# STM32F205RBT6 register map
File version: 1.0
Registers are 32-bit, access not given, reset 0x0 unless marked. A register's access mark holds for its fields unless they carry their own. Offsets are from the block's base; [hi:lo] are bit positions; {n}, {i} and the like mark numbered series; 'fields as' and 'values as' point back to an identical list.

## TIM12
Base 0x40001800
Same registers: TIM9 0x40014000
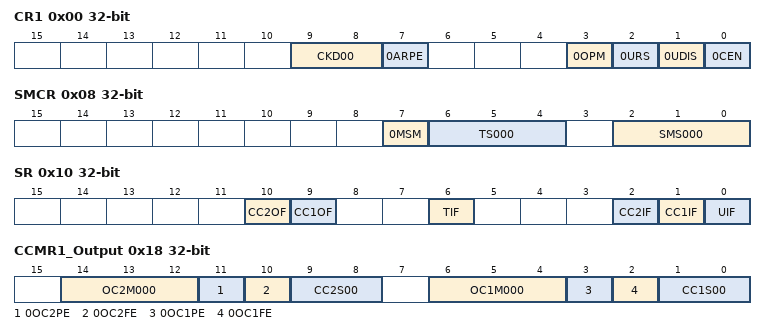
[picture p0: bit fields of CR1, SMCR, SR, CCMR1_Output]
0x00 CR1
  [9:8] CKD00, [7] 0ARPE, [3] 0OPM, [2] 0URS, [1] 0UDIS, [0] 0CEN
0x04 CR2
0x08 SMCR
  [7] 0MSM, [6:4] TS000, [2:0] SMS000
0x0C DIER
0x10 SR
  [10] CC2OF, [9] CC1OF, [6] TIF, [2] CC2IF, [1] CC1IF, [0] UIF
0x14 EGR
0x18 CCMR1_Output
  [14:12] OC2M000, [11] 0OC2PE, [10] 0OC2FE, [9:8] CC2S00, [6:4] OC1M000, [3] 0OC1PE, [2] 0OC1FE, [1:0] CC1S00
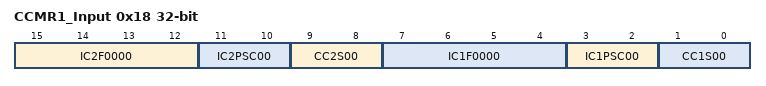
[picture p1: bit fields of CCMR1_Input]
0x18 CCMR1_Input
  [15:12] IC2F0000, [11:10] IC2PSC00, [9:8] CC2S00, [7:4] IC1F0000, [3:2] IC1PSC00, [1:0] CC1S00
0x20 CCER
0x24 CNT
0x28 PSC
0x2C ARR
0x34 CCR1
0x38 CCR2

## TIM13
Base 0x40001C00
Same registers: TIM14 0x40002000, TIM10 0x40014400, TIM11 0x40014800
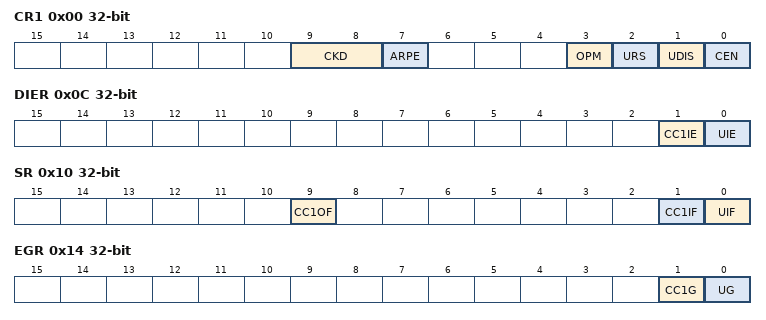
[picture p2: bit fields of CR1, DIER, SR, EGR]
0x00 CR1
  [9:8] CKD, [7] ARPE, [3] OPM, [2] URS, [1] UDIS, [0] CEN
0x08 SMCR
0x0C DIER
  [1] CC1IE, [0] UIE
0x10 SR
  [9] CC1OF, [1] CC1IF, [0] UIF
0x14 EGR
  [1] CC1G, [0] UG
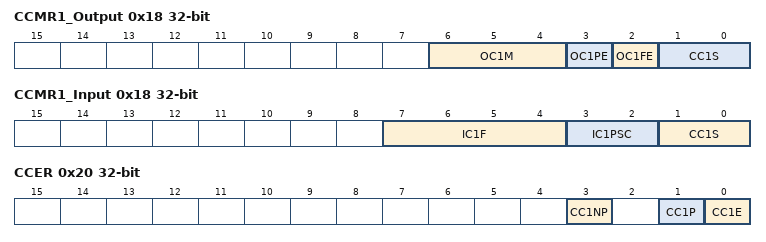
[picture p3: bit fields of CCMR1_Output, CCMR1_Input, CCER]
0x18 CCMR1_Output
  [6:4] OC1M, [3] OC1PE, [2] OC1FE, [1:0] CC1S
0x18 CCMR1_Input
  [7:4] IC1F, [3:2] IC1PSC, [1:0] CC1S
0x20 CCER
  [3] CC1NP, [1] CC1P, [0] CC1E
0x24 CNT
  [15:0] CNT
0x28 PSC
  [15:0] PSC
0x2C ARR
  [15:0] ARR
0x34 CCR1
  [15:0] CCR1
0x50 OR
  [1:0] TI1_RMP

## BKP
Base 0x40002800
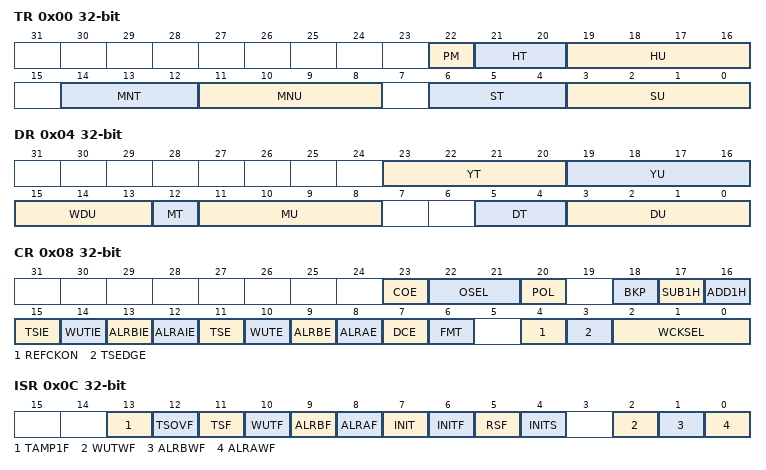
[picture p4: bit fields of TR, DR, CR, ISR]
0x00 TR
  [22] PM, [21:20] HT, [19:16] HU, [14:12] MNT, [11:8] MNU, [6:4] ST, [3:0] SU
0x04 DR
  [23:20] YT, [19:16] YU, [15:13] WDU, [12] MT, [11:8] MU, [5:4] DT, [3:0] DU
0x08 CR
  [23] COE, [22:21] OSEL, [20] POL, [18] BKP, [17] SUB1H, [16] ADD1H, [15] TSIE, [14] WUTIE, [13] ALRBIE, [12] ALRAIE, [11] TSE, [10] WUTE, [9] ALRBE, [8] ALRAE, [7] DCE, [6] FMT, [4] REFCKON, [3] TSEDGE, [2:0] WCKSEL
0x0C ISR
  [13] TAMP1F, [12] TSOVF, [11] TSF, [10] WUTF, [9] ALRBF, [8] ALRAF, [7] INIT, [6] INITF, [5] RSF, [4] INITS, [2] WUTWF, [1] ALRBWF, [0] ALRAWF
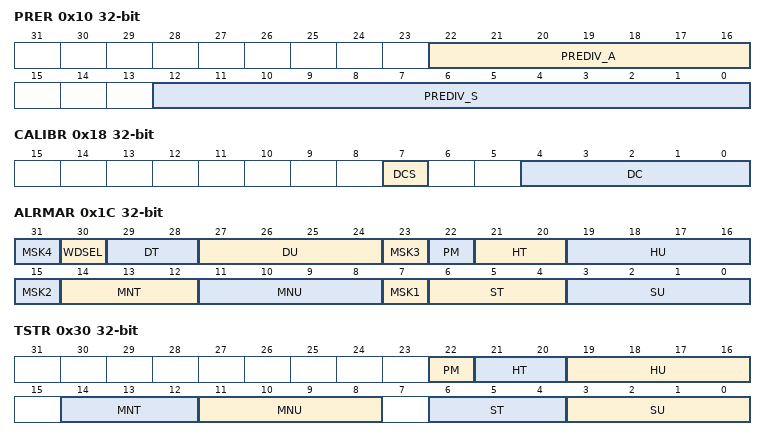
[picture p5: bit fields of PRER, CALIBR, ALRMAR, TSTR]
0x10 PRER
  [22:16] PREDIV_A, [12:0] PREDIV_S
0x14 WUTR
  [15:0] WUT
0x18 CALIBR
  [7] DCS, [4:0] DC
0x1C ALRMAR
  [8n-1] MSK{n} (n=1..4), [30] WDSEL, [29:28] DT, [27:24] DU, [22] PM, [21:20] HT, [19:16] HU, [14:12] MNT, [11:8] MNU, [6:4] ST, [3:0] SU
0x20 ALRMBR
  [31] MSK4, [30] WDSEL, [29:28] DT, [27:24] DU, [23] MSK3, [22] PM, [21:20] HT, [19:16] HU, [14:12] MNT, [11:8] MNU, [15:7] MSK2, [6:4] ST, [3:0] SU
0x24 WPR
  [7:0] KEY
0x30 TSTR
  fields as TR
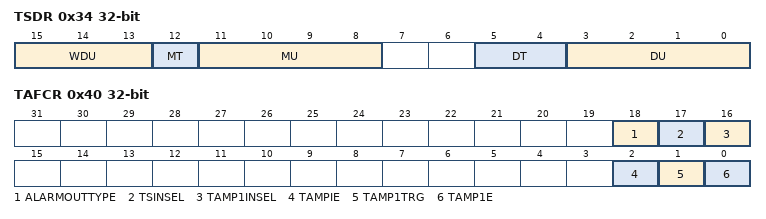
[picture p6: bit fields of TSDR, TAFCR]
0x34 TSDR
  [15:13] WDU, [12] MT, [11:8] MU, [5:4] DT, [3:0] DU
0x40 TAFCR
  [18] ALARMOUTTYPE, [17] TSINSEL, [16] TAMP1INSEL, [2] TAMPIE, [1] TAMP1TRG, [0] TAMP1E
{0x50+4i} BKP{i}R (i=0..19)
  [31:0] BKP

## RTC
Base 0x40002800
Registers as BKP; these are added or differ:
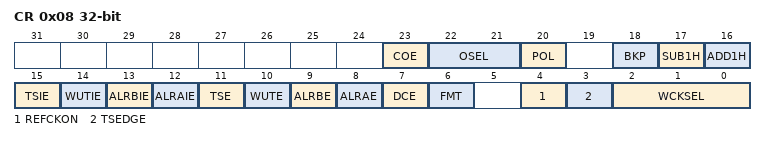
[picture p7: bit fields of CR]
0x08 CR
  fields as BKP.CR
{0x50+4i} BKP{i}R (i=0..19)
  [31:0] BKP

## WWDG
Base 0x40002C00
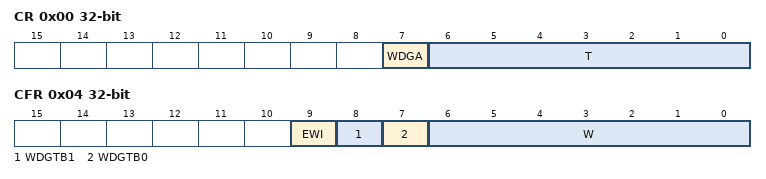
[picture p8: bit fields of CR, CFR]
0x00 CR
  [7] WDGA, [6:0] T
0x04 CFR
  [9] EWI, [8] WDGTB1, [7] WDGTB0, [6:0] W
0x08 SR
  [0] EWIF

## IWDG
Base 0x40003000
0x00 KR
  [15:0] KEY
0x04 PR
  [2:0] PR
0x08 RLR
  [11:0] RL
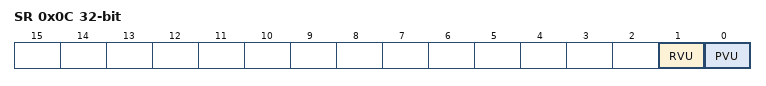
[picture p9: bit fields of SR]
0x0C SR
  [1] RVU, [0] PVU

## SPI2
Base 0x40003800
Same registers: SPI3 0x40003C00, SPI1 0x40013000
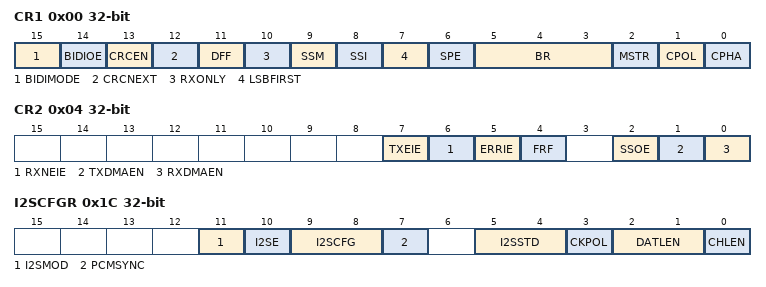
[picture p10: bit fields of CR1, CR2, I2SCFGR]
0x00 CR1
  [15] BIDIMODE, [14] BIDIOE, [13] CRCEN, [12] CRCNEXT, [11] DFF, [10] RXONLY, [9] SSM, [8] SSI, [7] LSBFIRST, [6] SPE, [5:3] BR, [2] MSTR, [1] CPOL, [0] CPHA
0x04 CR2
  [7] TXEIE, [6] RXNEIE, [5] ERRIE, [4] FRF, [2] SSOE, [1] TXDMAEN, [0] RXDMAEN
0x08 SR
0x0C DR
  [15:0] DR
0x10 CRCPR
  [15:0] CRCPOLY
0x14 RXCRCR
  [15:0] RxCRC
0x18 TXCRCR
  [15:0] TxCRC
0x1C I2SCFGR
  [11] I2SMOD, [10] I2SE, [9:8] I2SCFG, [7] PCMSYNC, [5:4] I2SSTD, [3] CKPOL, [2:1] DATLEN, [0] CHLEN
0x20 I2SPR

## USART2
Base 0x40004400
Same registers: USART3 0x40004800, UART4 0x40004C00, UART5 0x40005000, USART1 0x40011000, USART6 0x40011400
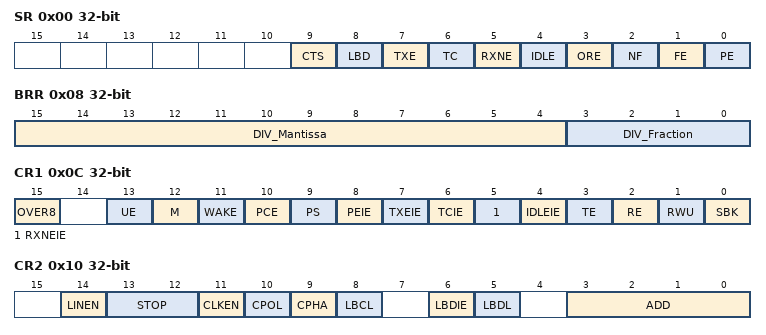
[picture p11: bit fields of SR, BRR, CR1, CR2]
0x00 SR
  [9] CTS, [8] LBD, [7] TXE, [6] TC, [5] RXNE, [4] IDLE, [3] ORE, [2] NF, [1] FE, [0] PE
0x04 DR
  [8:0] DR
0x08 BRR
  [15:4] DIV_Mantissa, [3:0] DIV_Fraction
0x0C CR1
  [15] OVER8, [13] UE, [12] M, [11] WAKE, [10] PCE, [9] PS, [8] PEIE, [7] TXEIE, [6] TCIE, [5] RXNEIE, [4] IDLEIE, [3] TE, [2] RE, [1] RWU, [0] SBK
0x10 CR2
  [14] LINEN, [13:12] STOP, [11] CLKEN, [10] CPOL, [9] CPHA, [8] LBCL, [6] LBDIE, [5] LBDL, [3:0] ADD
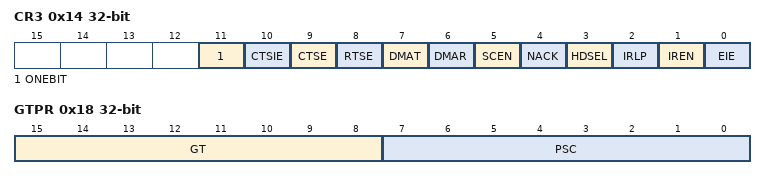
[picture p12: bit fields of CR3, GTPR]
0x14 CR3
  [11] ONEBIT, [10] CTSIE, [9] CTSE, [8] RTSE, [7] DMAT, [6] DMAR, [5] SCEN, [4] NACK, [3] HDSEL, [2] IRLP, [1] IREN, [0] EIE
0x18 GTPR
  [15:8] GT, [7:0] PSC
